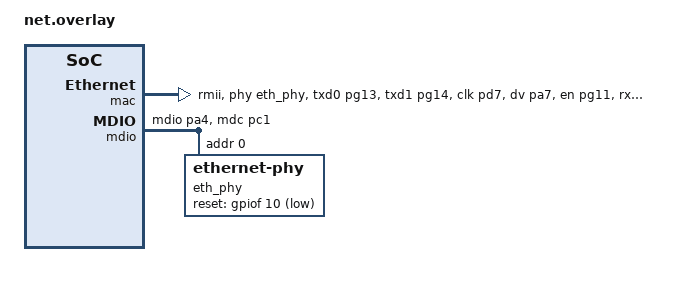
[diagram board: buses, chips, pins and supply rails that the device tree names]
&mac {
	pinctrl-0 = <&eth_rmii_txd0_pg13
		     &eth_rmii_txd1_pg14
		     &eth_rmii_ref_clk_pd7
		     &eth_rmii_crs_dv_pa7
		     &eth_rmii_tx_en_pg11
		     &eth_rmii_rxd0_pc4
		     &eth_rmii_rxd1_pc5>;
	pinctrl-names = "default";
	phy-connection-type = "rmii";
	phy-handle = <&eth_phy>;
	status = "okay";
};

&mdio {
	pinctrl-0 = <&eth_mdio_pa4 &eth_mdc_pc1>;
	pinctrl-names = "default";
	status = "okay";

	eth_phy: ethernet-phy@0 {
		compatible = "ethernet-phy";
		reg = <0x00>;
		reset-gpios = <&gpiof 10 GPIO_ACTIVE_LOW>;
	};
};


